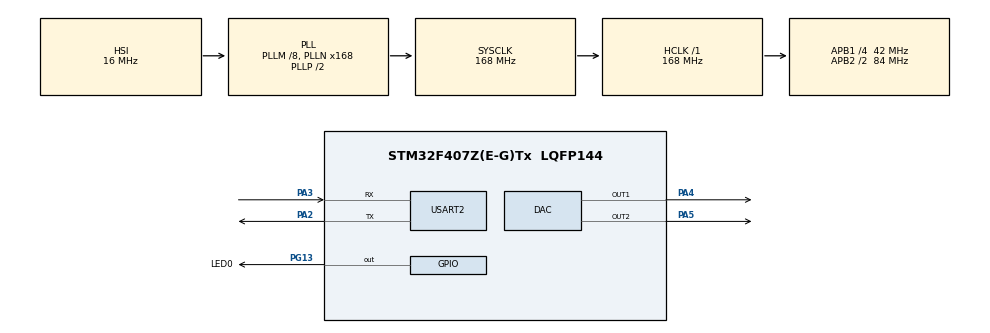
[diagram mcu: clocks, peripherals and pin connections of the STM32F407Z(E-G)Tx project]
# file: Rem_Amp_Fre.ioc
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DAC.DAC_OutputBuffer=DAC_OUTPUTBUFFER_DISABLE
DAC.DAC_OutputBuffer2=DAC_OUTPUTBUFFER_DISABLE
DAC.DAC_Trigger=DAC_TRIGGER_T6_TRGO
DAC.DAC_Trigger2=DAC_TRIGGER_T5_TRGO
Dma.DAC1.0.Direction=DMA_MEMORY_TO_PERIPH
Dma.DAC1.0.FIFOMode=DMA_FIFOMODE_DISABLE
Dma.DAC1.0.Instance=DMA1_Stream5
Dma.DAC1.0.MemDataAlignment=DMA_MDATAALIGN_HALFWORD
Dma.DAC1.0.MemInc=DMA_MINC_ENABLE
Dma.DAC1.0.Mode=DMA_CIRCULAR
Dma.DAC1.0.PeriphDataAlignment=DMA_PDATAALIGN_HALFWORD
Dma.DAC1.0.PeriphInc=DMA_PINC_DISABLE
Dma.DAC1.0.Priority=DMA_PRIORITY_LOW
Dma.DAC2.1.Direction=DMA_MEMORY_TO_PERIPH
Dma.DAC2.1.FIFOMode=DMA_FIFOMODE_DISABLE
Dma.DAC2.1.Instance=DMA1_Stream6
Dma.DAC2.1.MemDataAlignment=DMA_MDATAALIGN_HALFWORD
Dma.DAC2.1.MemInc=DMA_MINC_ENABLE
Dma.DAC2.1.Mode=DMA_CIRCULAR
Dma.DAC2.1.PeriphDataAlignment=DMA_PDATAALIGN_HALFWORD
Dma.DAC2.1.PeriphInc=DMA_PINC_DISABLE
Dma.DAC2.1.Priority=DMA_PRIORITY_LOW
Dma.Request0=DAC1
Dma.Request1=DAC2
Mcu.Family=STM32F4
Mcu.Name=STM32F407Z(E-G)Tx
Mcu.Package=LQFP144
NVIC.DMA1_Stream5_IRQn=true\:3\:0\:true\:false\:false\:false\:true\:true
NVIC.DMA1_Stream6_IRQn=true\:4\:0\:true\:false\:true\:true\:true\:true
NVIC.PriorityGroup=NVIC_PRIORITYGROUP_4
NVIC.TIM7_IRQn=true\:2\:0\:true\:false\:true\:true\:true\:true
NVIC.USART2_IRQn=true\:1\:0\:true\:false\:false\:true\:true\:true
PA13.Mode=Serial_Wire
PA13.Signal=SYS_JTMS-SWDIO
PA14.Mode=Serial_Wire
PA14.Signal=SYS_JTCK-SWCLK
PA2.Mode=Asynchronous
PA2.Signal=USART2_TX
PA3.Mode=Asynchronous
PA3.Signal=USART2_RX
PA4.Signal=COMP_DAC1_group
PA5.Signal=COMP_DAC2_group
PC14-OSC32_IN.Mode=LSE-External-Oscillator
PC14-OSC32_IN.Signal=RCC_OSC32_IN
PC15-OSC32_OUT.Mode=LSE-External-Oscillator
PC15-OSC32_OUT.Signal=RCC_OSC32_OUT
PG13.GPIO_Label=LED0
PG13.GPIO_PuPd=GPIO_PULLUP
PG13.GPIO_Speed=GPIO_SPEED_FREQ_LOW
PG13.PinState=GPIO_PIN_SET
PG13.Signal=GPIO_Output
PH0-OSC_IN.Mode=HSE-External-Oscillator
PH0-OSC_IN.Signal=RCC_OSC_IN
PH1-OSC_OUT.Mode=HSE-External-Oscillator
PH1-OSC_OUT.Signal=RCC_OSC_OUT
ProjectManager.HeapSize=0x200
ProjectManager.StackSize=0x800
ProjectManager.TargetToolchain=STM32CubeIDE
RCC.48MHZClocksFreq_Value=84000000
RCC.AHBFreq_Value=168000000
RCC.APB1CLKDivider=RCC_HCLK_DIV4
RCC.APB1Freq_Value=42000000
RCC.APB1TimFreq_Value=84000000
RCC.APB2CLKDivider=RCC_HCLK_DIV2
RCC.APB2Freq_Value=84000000
RCC.APB2TimFreq_Value=168000000
RCC.CortexFreq_Value=168000000
RCC.HCLKFreq_Value=168000000
RCC.HSE_VALUE=25000000
RCC.HSI_VALUE=16000000
RCC.PLLM=8
RCC.PLLN=168
RCC.SYSCLKFreq_VALUE=168000000
RCC.SYSCLKSource=RCC_SYSCLKSOURCE_PLLCLK
RCC.VCOOutputFreq_Value=336000000
SH.COMP_DAC1_group.0=DAC_OUT1,DAC_OUT1
SH.COMP_DAC2_group.0=DAC_OUT2,DAC_OUT2
STMicroelectronics.X-CUBE-ALGOBUILD.1.3.0.LibraryCcDSPOoLibraryJjDSPOoLibrary=true
TIM5.AutoReloadPreload=TIM_AUTORELOAD_PRELOAD_ENABLE
TIM5.Period=10-1
TIM5.Prescaler=336-1
TIM5.TIM_MasterOutputTrigger=TIM_TRGO_UPDATE
TIM6.AutoReloadPreload=TIM_AUTORELOAD_PRELOAD_ENABLE
TIM6.Period=40
TIM6.Prescaler=0
TIM6.TIM_MasterOutputTrigger=TIM_TRGO_UPDATE
TIM7.AutoReloadPreload=TIM_AUTORELOAD_PRELOAD_ENABLE
TIM7.Period=840-1
TIM7.Prescaler=1000-1
USART2.VirtualMode=VM_ASYNC
VP_STMicroelectronics.X-CUBE-ALGOBUILD_VS_DSPOoLibraryJjLibrary_1.3.0_1.3.0.Mode=DSPOoLibraryJjLibrary
VP_TIM5_VS_ClockSourceINT.Mode=Internal
VP_TIM6_VS_ClockSourceINT.Mode=Enable_Timer
VP_TIM7_VS_ClockSourceINT.Mode=Enable_Timer
board=custom

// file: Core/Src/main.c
/* USER CODE BEGIN Header */
/**
  ******************************************************************************
  * @file           : main.c
  * @brief          : Main program body
  ******************************************************************************
  * @attention
  *
  * Copyright (c) 2022 STMicroelectronics.
  * All rights reserved.
  *
  * This software is licensed under terms that can be found in the LICENSE file
  * in the root directory of this software component.
  * If no LICENSE file comes with this software, it is provided AS-IS.
  *
  ******************************************************************************
  */
/* USER CODE END Header */
#include "main.h"
#include "dac.h"
#include "dma.h"
#include "tim.h"
#include "usart.h"
#include "gpio.h"

/* USER CODE BEGIN Includes */
#include "base.h"
#include "stdio.h"
#include "string.h"
#include "cmd_process.h"
#include "hmi_user_uart.h"
#include "dds.h"
#include "arm_math.h"
#include "arm_common_tables.h"
/* USER CODE END Includes */

void SystemClock_Config(void);

int main(void)
{

  /* MCU Configuration--------------------------------------------------------*/

  /* Reset of all peripherals, Initializes the Flash interface and the Systick. */
  HAL_Init();

  /* Configure the system clock */
  SystemClock_Config();

  /* Initialize all configured peripherals */
  MX_GPIO_Init();
  MX_DMA_Init();
  MX_DAC_Init();
  MX_TIM6_Init();
  MX_TIM7_Init();
  MX_USART2_UART_Init();
  MX_TIM5_Init();
  /* USER CODE BEGIN 2 */
  TFT_Init();					  //串口屏初始化
  delay_init(168);                //初始化延时函数
  DAC_Init();
  /* USER CODE END 2 */

  /* Infinite loop */
  while (1)
  {

  }
}

void SystemClock_Config(void)
{
  RCC_OscInitTypeDef RCC_OscInitStruct = {0};
  RCC_ClkInitTypeDef RCC_ClkInitStruct = {0};

  /** Configure the main internal regulator output voltage
  */
  __HAL_RCC_PWR_CLK_ENABLE();
  __HAL_PWR_VOLTAGESCALING_CONFIG(PWR_REGULATOR_VOLTAGE_SCALE1);

  /** Initializes the RCC Oscillators according to the specified parameters
  * in the RCC_OscInitTypeDef structure.
  */
  RCC_OscInitStruct.OscillatorType = RCC_OSCILLATORTYPE_HSI;
  RCC_OscInitStruct.HSIState = RCC_HSI_ON;
  RCC_OscInitStruct.HSICalibrationValue = RCC_HSICALIBRATION_DEFAULT;
  RCC_OscInitStruct.PLL.PLLState = RCC_PLL_ON;
  RCC_OscInitStruct.PLL.PLLSource = RCC_PLLSOURCE_HSI;
  RCC_OscInitStruct.PLL.PLLM = 8;
  RCC_OscInitStruct.PLL.PLLN = 168;
  RCC_OscInitStruct.PLL.PLLP = RCC_PLLP_DIV2;
  RCC_OscInitStruct.PLL.PLLQ = 4;
  if (HAL_RCC_OscConfig(&RCC_OscInitStruct) != HAL_OK)
  {
    Error_Handler();
  }

  /** Initializes the CPU, AHB and APB buses clocks
  */
  RCC_ClkInitStruct.ClockType = RCC_CLOCKTYPE_HCLK|RCC_CLOCKTYPE_SYSCLK
                              |RCC_CLOCKTYPE_PCLK1|RCC_CLOCKTYPE_PCLK2;
  RCC_ClkInitStruct.SYSCLKSource = RCC_SYSCLKSOURCE_PLLCLK;
  RCC_ClkInitStruct.AHBCLKDivider = RCC_SYSCLK_DIV1;
  RCC_ClkInitStruct.APB1CLKDivider = RCC_HCLK_DIV4;
  RCC_ClkInitStruct.APB2CLKDivider = RCC_HCLK_DIV2;

  if (HAL_RCC_ClockConfig(&RCC_ClkInitStruct, FLASH_LATENCY_5) != HAL_OK)
  {
    Error_Handler();
  }
}

void Error_Handler(void)
{
  __disable_irq();
  while (1)
  {
  }
}
